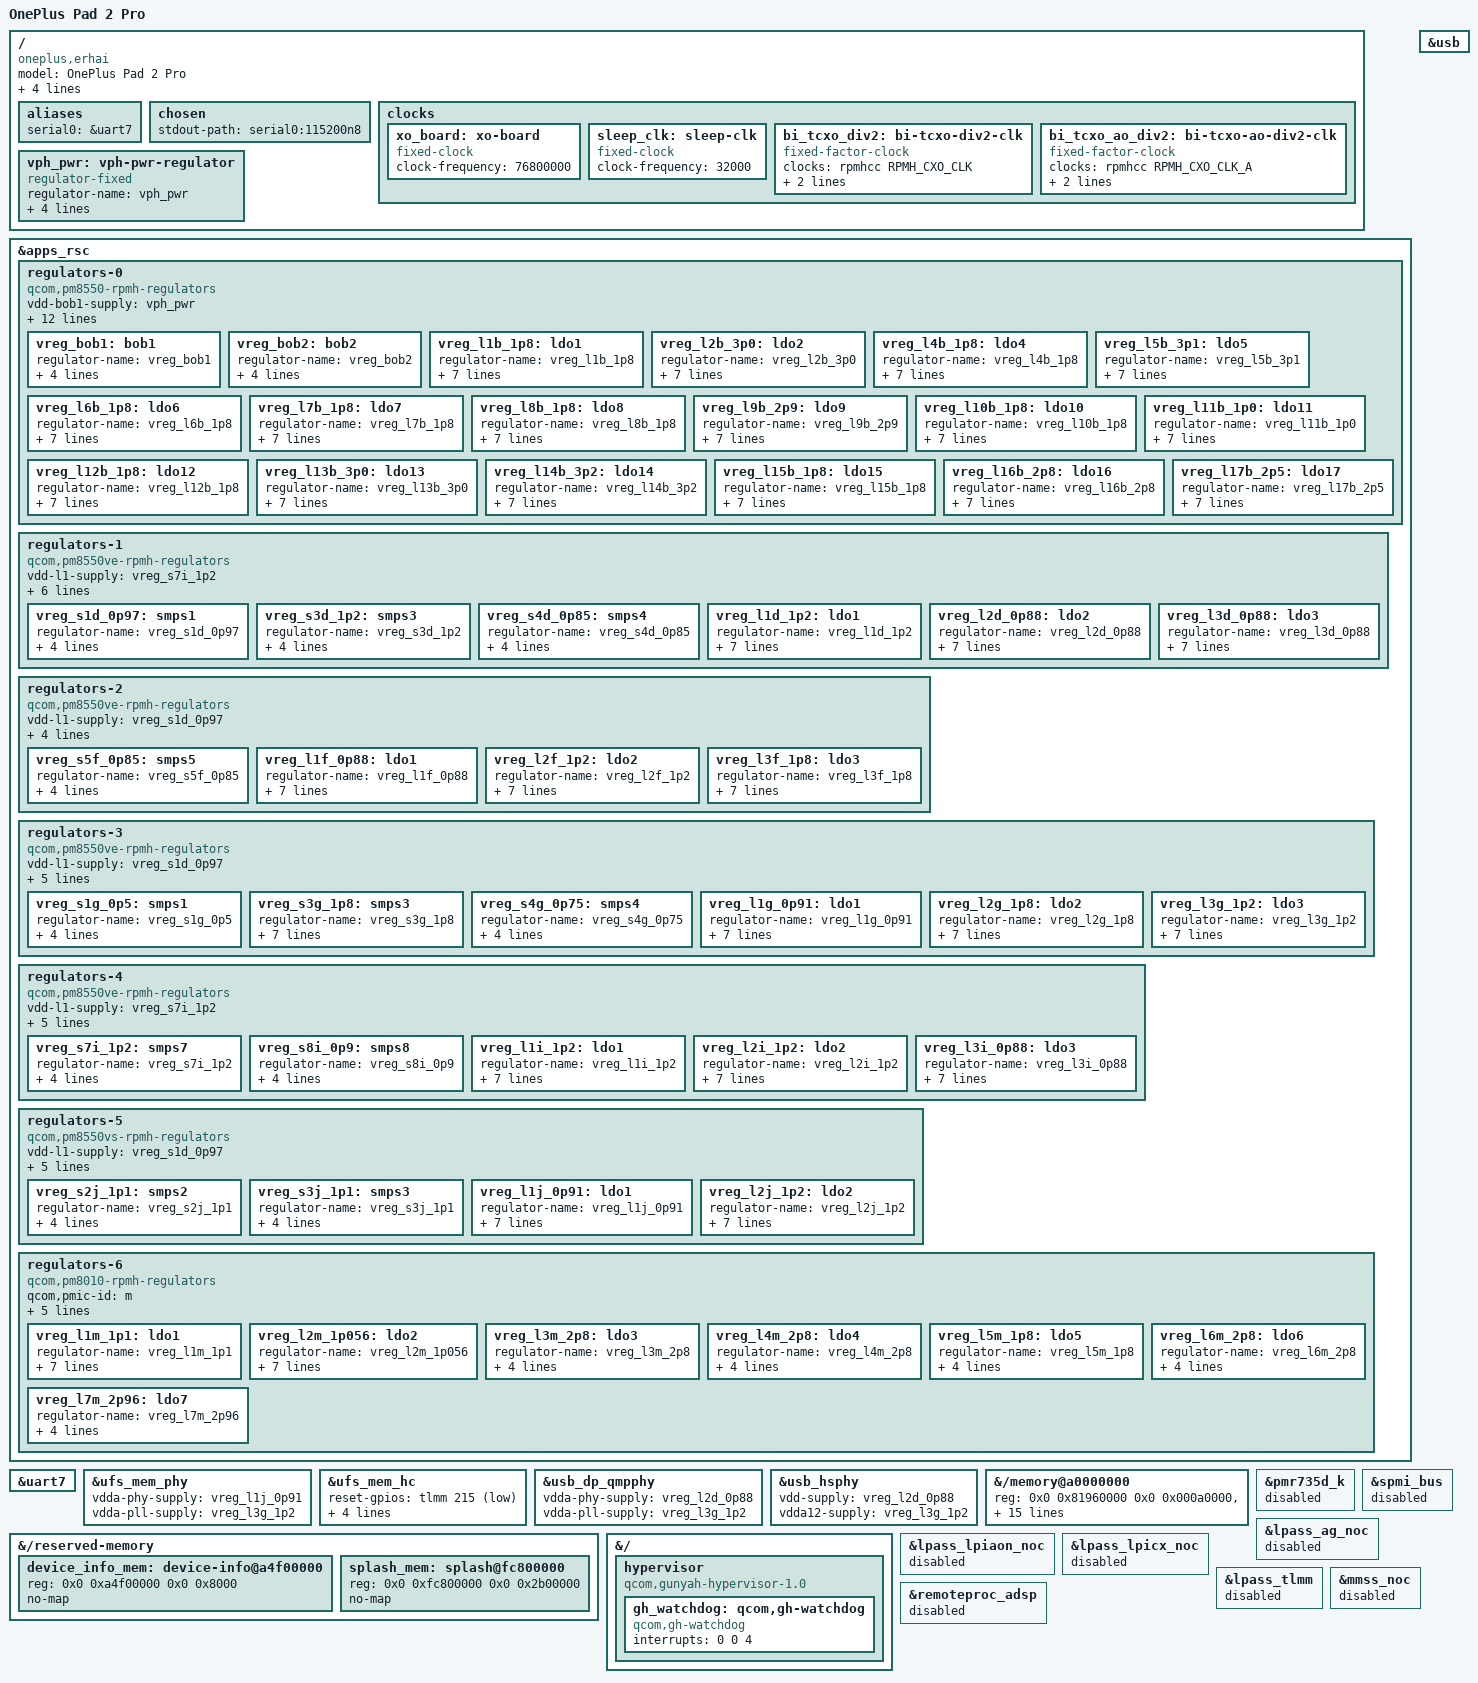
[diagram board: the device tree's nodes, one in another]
// SPDX-License-Identifier: BSD-3-Clause
/*
 * Copyright (c) 2026, OnePlus Pad 2 Pro (erhai) mainline contributors
 *
 * OnePlus Pad 2 Pro (codename "erhai") first-boot skeleton, structured
 * after the in-tree sm8750-xiaomi-piano.dts skeleton (same SM8750/sun
 * SoC). v0 scope: UART7 console, UFS storage, USB DWC3. Display/DSI,
 * touch, WLAN/BT, audio, sensors intentionally not enabled yet.
 *
 * Value provenance:
 *   (M) carried over from the in-tree SM8750 MTP / piano board files
 *   (R) cross-checked against the erhai live kernel DTB
 *       (vendor/erhai/board.dtb) and LineageOS
 *       android_kernel_oneplus_sm8750-devicetrees (erhai overlays)
 */

/dts-v1/;

#include <dt-bindings/gpio/gpio.h>
#include <dt-bindings/regulator/qcom,rpmh-regulator.h>
#include "sm8750.dtsi"
#include "pm8010.dtsi"
#include "pm8550.dtsi"
#define PMK8550VE_SID 8
#include "pm8550ve.dtsi"
#include "pmd8028.dtsi"
#include "pmih0108.dtsi"
#include "pmk8550.dtsi"
#include "pmr735d_a.dtsi"
#include "sm8750-pmics.dtsi"

/ {
	model = "OnePlus Pad 2 Pro";
	compatible = "oneplus,erhai", "qcom,sm8750";
	chassis-type = "tablet";

	/*
	 * (R) erhai live DTB / LineageOS sun-mtp-v8: SUN (0x26a) rev 1/2 and
	 * SUNP (0x27f) fallback entries. ABL-era matching is irrelevant on the
	 * SunUEFI handoff path; the kernel only needs sane IDs.
	 */
	qcom,msm-id = <0x100026a 0x20000>, <0x100027f 0x20000>;
	qcom,board-id = <0x40008 0>;

	aliases {
		serial0 = &uart7;
	};

	chosen {
		stdout-path = "serial0:115200n8";
	};

	clocks {
		xo_board: xo-board {
			compatible = "fixed-clock";
			clock-frequency = <76800000>;		/* (M) */
			#clock-cells = <0>;
		};

		sleep_clk: sleep-clk {
			compatible = "fixed-clock";
			clock-frequency = <32000>;		/* (M) */
			#clock-cells = <0>;
		};

		bi_tcxo_div2: bi-tcxo-div2-clk {
			compatible = "fixed-factor-clock";
			#clock-cells = <0>;

			clocks = <&rpmhcc RPMH_CXO_CLK>;
			clock-mult = <1>;
			clock-div = <2>;
		};

		bi_tcxo_ao_div2: bi-tcxo-ao-div2-clk {
			compatible = "fixed-factor-clock";
			#clock-cells = <0>;

			clocks = <&rpmhcc RPMH_CXO_CLK_A>;
			clock-mult = <1>;
			clock-div = <2>;
		};
	};

	vph_pwr: vph-pwr-regulator {
		compatible = "regulator-fixed";

		regulator-name = "vph_pwr";
		regulator-min-microvolt = <3700000>;		/* (M) */
		regulator-max-microvolt = <3700000>;		/* (M) */

		regulator-always-on;
		regulator-boot-on;
	};
};

&apps_rsc {
	/*
	 * Regulator network follows the SM8750 MTP power grid (v8 variant,
	 * same grid downstream sun-mtp-v8). Per-rail assignment for the
	 * piano board is carried from MTP and not yet device-verified. (M)
	 * Open question #10 tracks per-rail validation.
	 */
	regulators-0 {
		compatible = "qcom,pm8550-rpmh-regulators";

		vdd-bob1-supply = <&vph_pwr>;
		vdd-bob2-supply = <&vph_pwr>;
		vdd-l1-l4-l10-supply = <&vreg_s3g_1p8>;
		vdd-l2-l13-l14-supply = <&vreg_bob1>;
		vdd-l3-supply = <&vreg_s7i_1p2>;
		vdd-l5-l16-supply = <&vreg_bob1>;
		vdd-l6-l7-supply = <&vreg_bob1>;
		vdd-l8-l9-supply = <&vreg_bob1>;
		vdd-l11-supply = <&vreg_s7i_1p2>;
		vdd-l12-supply = <&vreg_s3g_1p8>;
		vdd-l15-supply = <&vreg_s3g_1p8>;
		vdd-l17-supply = <&vreg_bob2>;

		qcom,pmic-id = "b";

		vreg_bob1: bob1 {
			regulator-name = "vreg_bob1";
			regulator-min-microvolt = <3008000>;
			regulator-max-microvolt = <4000000>;
			regulator-initial-mode = <RPMH_REGULATOR_MODE_HPM>;
		};

		vreg_bob2: bob2 {
			regulator-name = "vreg_bob2";
			regulator-min-microvolt = <2704000>;
			regulator-max-microvolt = <3008000>;
			regulator-initial-mode = <RPMH_REGULATOR_MODE_HPM>;
		};

		vreg_l1b_1p8: ldo1 {
			regulator-name = "vreg_l1b_1p8";
			regulator-min-microvolt = <1800000>;
			regulator-max-microvolt = <1800000>;
			regulator-initial-mode = <RPMH_REGULATOR_MODE_HPM>;
			regulator-allow-set-load;
			regulator-allowed-modes = <RPMH_REGULATOR_MODE_LPM
						   RPMH_REGULATOR_MODE_HPM>;
		};

		vreg_l2b_3p0: ldo2 {
			regulator-name = "vreg_l2b_3p0";
			regulator-min-microvolt = <3008000>;
			regulator-max-microvolt = <3048000>;
			regulator-initial-mode = <RPMH_REGULATOR_MODE_HPM>;
			regulator-allow-set-load;
			regulator-allowed-modes = <RPMH_REGULATOR_MODE_LPM
						   RPMH_REGULATOR_MODE_HPM>;
		};

		vreg_l4b_1p8: ldo4 {
			regulator-name = "vreg_l4b_1p8";
			regulator-min-microvolt = <1800000>;
			regulator-max-microvolt = <1800000>;
			regulator-initial-mode = <RPMH_REGULATOR_MODE_HPM>;
			regulator-allow-set-load;
			regulator-allowed-modes = <RPMH_REGULATOR_MODE_LPM
						   RPMH_REGULATOR_MODE_HPM>;
		};

		vreg_l5b_3p1: ldo5 {
			regulator-name = "vreg_l5b_3p1";
			regulator-min-microvolt = <3100000>;
			regulator-max-microvolt = <3148000>;
			regulator-initial-mode = <RPMH_REGULATOR_MODE_HPM>;
			regulator-allow-set-load;
			regulator-allowed-modes = <RPMH_REGULATOR_MODE_LPM
						   RPMH_REGULATOR_MODE_HPM>;
		};

		vreg_l6b_1p8: ldo6 {
			regulator-name = "vreg_l6b_1p8";
			regulator-min-microvolt = <1800000>;
			regulator-max-microvolt = <3008000>;
			regulator-initial-mode = <RPMH_REGULATOR_MODE_HPM>;
			regulator-allow-set-load;
			regulator-allowed-modes = <RPMH_REGULATOR_MODE_LPM
						   RPMH_REGULATOR_MODE_HPM>;
		};

		vreg_l7b_1p8: ldo7 {
			regulator-name = "vreg_l7b_1p8";
			regulator-min-microvolt = <1800000>;
			regulator-max-microvolt = <3008000>;
			regulator-initial-mode = <RPMH_REGULATOR_MODE_HPM>;
			regulator-allow-set-load;
			regulator-allowed-modes = <RPMH_REGULATOR_MODE_LPM
						   RPMH_REGULATOR_MODE_HPM>;
		};

		vreg_l8b_1p8: ldo8 {
			regulator-name = "vreg_l8b_1p8";
			regulator-min-microvolt = <1800000>;
			regulator-max-microvolt = <3008000>;
			regulator-initial-mode = <RPMH_REGULATOR_MODE_HPM>;
			regulator-allow-set-load;
			regulator-allowed-modes = <RPMH_REGULATOR_MODE_LPM
						   RPMH_REGULATOR_MODE_HPM>;
		};

		vreg_l9b_2p9: ldo9 {
			regulator-name = "vreg_l9b_2p9";
			regulator-min-microvolt = <2960000>;
			regulator-max-microvolt = <3008000>;
			regulator-initial-mode = <RPMH_REGULATOR_MODE_HPM>;
			regulator-allow-set-load;
			regulator-allowed-modes = <RPMH_REGULATOR_MODE_LPM
						   RPMH_REGULATOR_MODE_HPM>;
		};

		vreg_l10b_1p8: ldo10 {
			regulator-name = "vreg_l10b_1p8";
			regulator-min-microvolt = <1800000>;
			regulator-max-microvolt = <1800000>;
			regulator-initial-mode = <RPMH_REGULATOR_MODE_HPM>;
			regulator-allow-set-load;
			regulator-allowed-modes = <RPMH_REGULATOR_MODE_LPM
						   RPMH_REGULATOR_MODE_HPM>;
		};

		vreg_l11b_1p0: ldo11 {
			regulator-name = "vreg_l11b_1p0";
			regulator-min-microvolt = <1064000>;
			regulator-max-microvolt = <1292000>;
			regulator-initial-mode = <RPMH_REGULATOR_MODE_HPM>;
			regulator-allow-set-load;
			regulator-allowed-modes = <RPMH_REGULATOR_MODE_LPM
						   RPMH_REGULATOR_MODE_HPM>;
		};

		vreg_l12b_1p8: ldo12 {
			regulator-name = "vreg_l12b_1p8";
			regulator-min-microvolt = <1200000>;
			regulator-max-microvolt = <1800000>;
			regulator-initial-mode = <RPMH_REGULATOR_MODE_HPM>;
			regulator-allow-set-load;
			regulator-allowed-modes = <RPMH_REGULATOR_MODE_LPM
						   RPMH_REGULATOR_MODE_HPM>;
		};

		vreg_l13b_3p0: ldo13 {
			regulator-name = "vreg_l13b_3p0";
			regulator-min-microvolt = <3000000>;
			regulator-max-microvolt = <3000000>;
			regulator-initial-mode = <RPMH_REGULATOR_MODE_HPM>;
			regulator-allow-set-load;
			regulator-allowed-modes = <RPMH_REGULATOR_MODE_LPM
						   RPMH_REGULATOR_MODE_HPM>;
		};

		vreg_l14b_3p2: ldo14 {
			regulator-name = "vreg_l14b_3p2";
			regulator-min-microvolt = <3200000>;
			regulator-max-microvolt = <3200000>;
			regulator-initial-mode = <RPMH_REGULATOR_MODE_HPM>;
			regulator-allow-set-load;
			regulator-allowed-modes = <RPMH_REGULATOR_MODE_LPM
						   RPMH_REGULATOR_MODE_HPM>;
		};

		vreg_l15b_1p8: ldo15 {
			regulator-name = "vreg_l15b_1p8";
			regulator-min-microvolt = <1800000>;
			regulator-max-microvolt = <1800000>;
			regulator-initial-mode = <RPMH_REGULATOR_MODE_HPM>;
			regulator-allow-set-load;
			regulator-allowed-modes = <RPMH_REGULATOR_MODE_LPM
						   RPMH_REGULATOR_MODE_HPM>;
		};

		vreg_l16b_2p8: ldo16 {
			regulator-name = "vreg_l16b_2p8";
			regulator-min-microvolt = <2800000>;
			regulator-max-microvolt = <2800000>;
			regulator-initial-mode = <RPMH_REGULATOR_MODE_HPM>;
			regulator-allow-set-load;
			regulator-allowed-modes = <RPMH_REGULATOR_MODE_LPM
						   RPMH_REGULATOR_MODE_HPM>;
		};

		vreg_l17b_2p5: ldo17 {
			regulator-name = "vreg_l17b_2p5";
			regulator-min-microvolt = <2504000>;
			regulator-max-microvolt = <2504000>;
			regulator-initial-mode = <RPMH_REGULATOR_MODE_HPM>;
			regulator-allow-set-load;
			regulator-allowed-modes = <RPMH_REGULATOR_MODE_LPM
						   RPMH_REGULATOR_MODE_HPM>;
		};
	};

	regulators-1 {
		compatible = "qcom,pm8550ve-rpmh-regulators";

		vdd-l1-supply = <&vreg_s7i_1p2>;
		vdd-l2-supply = <&vreg_s1d_0p97>;
		vdd-l3-supply = <&vreg_s1d_0p97>;
		vdd-s1-supply = <&vph_pwr>;
		vdd-s3-supply = <&vph_pwr>;
		vdd-s4-supply = <&vph_pwr>;

		qcom,pmic-id = "d";

		vreg_s1d_0p97: smps1 {
			regulator-name = "vreg_s1d_0p97";
			regulator-min-microvolt = <880000>;
			regulator-max-microvolt = <1100000>;
			regulator-initial-mode = <RPMH_REGULATOR_MODE_HPM>;
		};

		vreg_s3d_1p2: smps3 {
			regulator-name = "vreg_s3d_1p2";
			regulator-min-microvolt = <1200000>;
			regulator-max-microvolt = <1300000>;
			regulator-initial-mode = <RPMH_REGULATOR_MODE_HPM>;
		};

		vreg_s4d_0p85: smps4 {
			regulator-name = "vreg_s4d_0p85";
			regulator-min-microvolt = <852000>;
			regulator-max-microvolt = <1036000>;
			regulator-initial-mode = <RPMH_REGULATOR_MODE_HPM>;
		};

		vreg_l1d_1p2: ldo1 {
			regulator-name = "vreg_l1d_1p2";
			regulator-min-microvolt = <1200000>;
			regulator-max-microvolt = <1200000>;
			regulator-initial-mode = <RPMH_REGULATOR_MODE_HPM>;
			regulator-allow-set-load;
			regulator-allowed-modes = <RPMH_REGULATOR_MODE_LPM
						   RPMH_REGULATOR_MODE_HPM>;
		};

		vreg_l2d_0p88: ldo2 {
			regulator-name = "vreg_l2d_0p88";
			regulator-min-microvolt = <880000>;
			regulator-max-microvolt = <912000>;
			regulator-initial-mode = <RPMH_REGULATOR_MODE_HPM>;
			regulator-allow-set-load;
			regulator-allowed-modes = <RPMH_REGULATOR_MODE_LPM
						   RPMH_REGULATOR_MODE_HPM>;
		};

		vreg_l3d_0p88: ldo3 {
			regulator-name = "vreg_l3d_0p88";
			regulator-min-microvolt = <880000>;
			regulator-max-microvolt = <920000>;
			regulator-initial-mode = <RPMH_REGULATOR_MODE_HPM>;
			regulator-allow-set-load;
			regulator-allowed-modes = <RPMH_REGULATOR_MODE_LPM
						   RPMH_REGULATOR_MODE_HPM>;
		};
	};

	regulators-2 {
		compatible = "qcom,pm8550ve-rpmh-regulators";

		vdd-l1-supply = <&vreg_s1d_0p97>;
		vdd-l2-supply = <&vreg_s7i_1p2>;
		vdd-l3-supply = <&vreg_s3g_1p8>;
		vdd-s5-supply = <&vph_pwr>;

		qcom,pmic-id = "f";

		vreg_s5f_0p85: smps5 {
			regulator-name = "vreg_s5f_0p85";
			regulator-min-microvolt = <852000>;
			regulator-max-microvolt = <1000000>;
			regulator-initial-mode = <RPMH_REGULATOR_MODE_HPM>;
		};

		vreg_l1f_0p88: ldo1 {
			regulator-name = "vreg_l1f_0p88";
			regulator-min-microvolt = <880000>;
			regulator-max-microvolt = <920000>;
			regulator-initial-mode = <RPMH_REGULATOR_MODE_HPM>;
			regulator-allow-set-load;
			regulator-allowed-modes = <RPMH_REGULATOR_MODE_LPM
						   RPMH_REGULATOR_MODE_HPM>;
		};

		vreg_l2f_1p2: ldo2 {
			regulator-name = "vreg_l2f_1p2";
			regulator-min-microvolt = <1200000>;
			regulator-max-microvolt = <1200000>;
			regulator-initial-mode = <RPMH_REGULATOR_MODE_HPM>;
			regulator-allow-set-load;
			regulator-allowed-modes = <RPMH_REGULATOR_MODE_LPM
						   RPMH_REGULATOR_MODE_HPM>;
		};

		vreg_l3f_1p8: ldo3 {
			regulator-name = "vreg_l3f_1p8";
			regulator-min-microvolt = <1800000>;
			regulator-max-microvolt = <1800000>;
			regulator-initial-mode = <RPMH_REGULATOR_MODE_HPM>;
			regulator-allow-set-load;
			regulator-allowed-modes = <RPMH_REGULATOR_MODE_LPM
						   RPMH_REGULATOR_MODE_HPM>;
		};
	};

	regulators-3 {
		compatible = "qcom,pm8550ve-rpmh-regulators";

		vdd-l1-supply = <&vreg_s1d_0p97>;
		vdd-l2-supply = <&vreg_s3g_1p8>;
		vdd-l3-supply = <&vreg_s7i_1p2>;
		vdd-s1-supply = <&vph_pwr>;
		vdd-s3-supply = <&vph_pwr>;

		qcom,pmic-id = "g";

		vreg_s1g_0p5: smps1 {
			regulator-name = "vreg_s1g_0p5";
			regulator-min-microvolt = <300000>;
			regulator-max-microvolt = <700000>;
			regulator-initial-mode = <RPMH_REGULATOR_MODE_HPM>;
		};

		vreg_s3g_1p8: smps3 {
			regulator-name = "vreg_s3g_1p8";
			regulator-min-microvolt = <1856000>;
			regulator-max-microvolt = <2000000>;
			regulator-initial-mode = <RPMH_REGULATOR_MODE_LPM>;
			regulator-allow-set-load;
			regulator-allowed-modes = <RPMH_REGULATOR_MODE_LPM
						   RPMH_REGULATOR_MODE_HPM>;
		};

		vreg_s4g_0p75: smps4 {
			regulator-name = "vreg_s4g_0p75";
			regulator-min-microvolt = <300000>;
			regulator-max-microvolt = <900000>;
			regulator-initial-mode = <RPMH_REGULATOR_MODE_HPM>;
		};

		vreg_l1g_0p91: ldo1 {
			regulator-name = "vreg_l1g_0p91";
			regulator-min-microvolt = <912000>;
			regulator-max-microvolt = <936000>;
			regulator-initial-mode = <RPMH_REGULATOR_MODE_HPM>;
			regulator-allow-set-load;
			regulator-allowed-modes = <RPMH_REGULATOR_MODE_LPM
						   RPMH_REGULATOR_MODE_HPM>;
		};

		vreg_l2g_1p8: ldo2 {
			regulator-name = "vreg_l2g_1p8";
			regulator-min-microvolt = <1200000>;
			regulator-max-microvolt = <1860000>;
			regulator-initial-mode = <RPMH_REGULATOR_MODE_HPM>;
			regulator-allow-set-load;
			regulator-allowed-modes = <RPMH_REGULATOR_MODE_LPM
						   RPMH_REGULATOR_MODE_HPM>;
		};

		vreg_l3g_1p2: ldo3 {
			regulator-name = "vreg_l3g_1p2";
			regulator-min-microvolt = <1200000>;
			regulator-max-microvolt = <1256000>;
			regulator-initial-mode = <RPMH_REGULATOR_MODE_HPM>;
			regulator-allow-set-load;
			regulator-allowed-modes = <RPMH_REGULATOR_MODE_LPM
						   RPMH_REGULATOR_MODE_HPM>;
		};
	};

	regulators-4 {
		compatible = "qcom,pm8550ve-rpmh-regulators";

		vdd-l1-supply = <&vreg_s7i_1p2>;
		vdd-l2-supply = <&vreg_s7i_1p2>;
		vdd-l3-supply = <&vreg_s1d_0p97>;
		vdd-s7-supply = <&vph_pwr>;
		vdd-s8-supply = <&vph_pwr>;

		qcom,pmic-id = "i";

		vreg_s7i_1p2: smps7 {
			regulator-name = "vreg_s7i_1p2";
			regulator-min-microvolt = <1224000>;
			regulator-max-microvolt = <1340000>;
			regulator-initial-mode = <RPMH_REGULATOR_MODE_HPM>;
		};

		vreg_s8i_0p9: smps8 {
			regulator-name = "vreg_s8i_0p9";
			regulator-min-microvolt = <900000>;
			regulator-max-microvolt = <972000>;
			regulator-initial-mode = <RPMH_REGULATOR_MODE_HPM>;
		};

		vreg_l1i_1p2: ldo1 {
			regulator-name = "vreg_l1i_1p2";
			regulator-min-microvolt = <1200000>;
			regulator-max-microvolt = <1200000>;
			regulator-initial-mode = <RPMH_REGULATOR_MODE_HPM>;
			regulator-allow-set-load;
			regulator-allowed-modes = <RPMH_REGULATOR_MODE_LPM
						   RPMH_REGULATOR_MODE_HPM>;
		};

		vreg_l2i_1p2: ldo2 {
			regulator-name = "vreg_l2i_1p2";
			regulator-min-microvolt = <1200000>;
			regulator-max-microvolt = <1200000>;
			regulator-initial-mode = <RPMH_REGULATOR_MODE_HPM>;
			regulator-allow-set-load;
			regulator-allowed-modes = <RPMH_REGULATOR_MODE_LPM
						   RPMH_REGULATOR_MODE_HPM>;
		};

		vreg_l3i_0p88: ldo3 {
			regulator-name = "vreg_l3i_0p88";
			regulator-min-microvolt = <880000>;
			regulator-max-microvolt = <912000>;
			regulator-initial-mode = <RPMH_REGULATOR_MODE_HPM>;
			regulator-allow-set-load;
			regulator-allowed-modes = <RPMH_REGULATOR_MODE_LPM
						   RPMH_REGULATOR_MODE_HPM>;
		};
	};

	regulators-5 {
		compatible = "qcom,pm8550vs-rpmh-regulators";

		vdd-l1-supply = <&vreg_s1d_0p97>;
		vdd-l2-supply = <&vreg_s7i_1p2>;
		vdd-s2-supply = <&vph_pwr>;
		vdd-s3-supply = <&vph_pwr>;
		vdd-s4-supply = <&vph_pwr>;

		qcom,pmic-id = "j";

		vreg_s2j_1p1: smps2 {
			regulator-name = "vreg_s2j_1p1";
			regulator-min-microvolt = <1000000>;
			regulator-max-microvolt = <1100000>;
			regulator-initial-mode = <RPMH_REGULATOR_MODE_HPM>;
		};

		vreg_s3j_1p1: smps3 {
			regulator-name = "vreg_s3j_1p1";
			regulator-min-microvolt = <1000000>;
			regulator-max-microvolt = <1100000>;
			regulator-initial-mode = <RPMH_REGULATOR_MODE_HPM>;
		};

		vreg_l1j_0p91: ldo1 {
			regulator-name = "vreg_l1j_0p91";
			regulator-min-microvolt = <880000>;
			regulator-max-microvolt = <920000>;
			regulator-initial-mode = <RPMH_REGULATOR_MODE_HPM>;
			regulator-allow-set-load;
			regulator-allowed-modes = <RPMH_REGULATOR_MODE_LPM
						   RPMH_REGULATOR_MODE_HPM>;
		};

		vreg_l2j_1p2: ldo2 {
			regulator-name = "vreg_l2j_1p2";
			regulator-min-microvolt = <1200000>;
			regulator-max-microvolt = <1200000>;
			regulator-initial-mode = <RPMH_REGULATOR_MODE_HPM>;
			regulator-allow-set-load;
			regulator-allowed-modes = <RPMH_REGULATOR_MODE_LPM
						   RPMH_REGULATOR_MODE_HPM>;
		};
	};

	regulators-6 {
		compatible = "qcom,pm8010-rpmh-regulators";
		qcom,pmic-id = "m";

		vdd-l1-l2-supply = <&vreg_s7i_1p2>;
		vdd-l3-l4-supply = <&vreg_bob2>;
		vdd-l5-supply = <&vreg_s3g_1p8>;
		vdd-l6-supply = <&vreg_bob1>;
		vdd-l7-supply = <&vreg_bob1>;

		vreg_l1m_1p1: ldo1 {
			regulator-name = "vreg_l1m_1p1";
			regulator-min-microvolt = <1104000>;
			regulator-max-microvolt = <1104000>;
			regulator-initial-mode = <RPMH_REGULATOR_MODE_HPM>;
			regulator-allow-set-load;
			regulator-allowed-modes = <RPMH_REGULATOR_MODE_LPM
						   RPMH_REGULATOR_MODE_HPM>;
		};

		vreg_l2m_1p056: ldo2 {
			regulator-name = "vreg_l2m_1p056";
			regulator-min-microvolt = <1056000>;
			regulator-max-microvolt = <1056000>;
			regulator-initial-mode = <RPMH_REGULATOR_MODE_HPM>;
			regulator-allow-set-load;
			regulator-allowed-modes = <RPMH_REGULATOR_MODE_LPM
						   RPMH_REGULATOR_MODE_HPM>;
		};

		vreg_l3m_2p8: ldo3 {
			regulator-name = "vreg_l3m_2p8";
			regulator-min-microvolt = <2800000>;
			regulator-max-microvolt = <2800000>;
			regulator-initial-mode = <RPMH_REGULATOR_MODE_HPM>;
		};

		vreg_l4m_2p8: ldo4 {
			regulator-name = "vreg_l4m_2p8";
			regulator-min-microvolt = <2800000>;
			regulator-max-microvolt = <2800000>;
			regulator-initial-mode = <RPMH_REGULATOR_MODE_HPM>;
		};

		vreg_l5m_1p8: ldo5 {
			regulator-name = "vreg_l5m_1p8";
			regulator-min-microvolt = <1800000>;
			regulator-max-microvolt = <1800000>;
			regulator-initial-mode = <RPMH_REGULATOR_MODE_HPM>;
		};

		vreg_l6m_2p8: ldo6 {
			regulator-name = "vreg_l6m_2p8";
			regulator-min-microvolt = <2800000>;
			regulator-max-microvolt = <2800000>;
			regulator-initial-mode = <RPMH_REGULATOR_MODE_HPM>;
		};

		vreg_l7m_2p96: ldo7 {
			regulator-name = "vreg_l7m_2p96";
			regulator-min-microvolt = <2960000>;
			regulator-max-microvolt = <2960000>;
			regulator-initial-mode = <RPMH_REGULATOR_MODE_HPM>;
		};
	};

	/* No regulators-7 (pmic-id "n"): piano omits the second PM8010 die. (R) */
};
&uart7 {
	status = "okay";
};

/*
 * (M) SoC-generic UFS rails from the MTP/piano board file. The erhai live
 * DTB names vcc/vccq via phandles into the same PMIC rail set; refine the
 * exact rails after first boot.
 */
&ufs_mem_phy {
	vdda-phy-supply = <&vreg_l1j_0p91>;		/* (M) */
	vdda-pll-supply = <&vreg_l3g_1p2>;		/* (M) */

	status = "okay";
};

&ufs_mem_hc {
	reset-gpios = <&tlmm 215 GPIO_ACTIVE_LOW>;	/* (M) */

	vcc-supply = <&vreg_l17b_2p5>;			/* (M) */
	vcc-max-microamp = <1300000>;
	vccq-supply = <&vreg_l1d_1p2>;			/* (M) */
	vccq-max-microamp = <1200000>;

	status = "okay";
};

&usb {
	status = "okay";
};

&usb_dp_qmpphy {
	vdda-phy-supply = <&vreg_l2d_0p88>;		/* (M) */
	vdda-pll-supply = <&vreg_l3g_1p2>;		/* (M) */

	status = "okay";
};

&usb_hsphy {
	vdd-supply = <&vreg_l2d_0p88>;			/* (M) */
	vdda12-supply = <&vreg_l3g_1p2>;		/* (M) */

	status = "okay";
};

/*
 * Real erhai DRAM map, copied verbatim from the live vendor FDT
 * (vendor/erhai/board.dtb, /memory reg). ABL fills this for the Android boot;
 * a raw UEFI handoff must ship it in the DTB instead of growing the property
 * at runtime: growing it shifts libfdt node offsets, and the following
 * /chosen writes then land on stale nodes (FDT_ERR_BADOFFSET / wrong
 * bootargs). The stage-0 boot manager no longer patches /memory.
 */
&{/memory@a0000000} {
	reg = <0x0 0x81960000 0x0 0x000a0000>,
	      <0x0 0x81a40000 0x0 0x001c0000>,
	      <0x0 0x81cf4000 0x0 0x0000c000>,
	      <0x0 0x82460000 0x0 0x00040000>,
	      <0x0 0xbe360000 0x0 0x16ac3000>,
	      <0x0 0xd5100000 0x0 0x02f00000>,
	      <0x0 0xd8600000 0x0 0x00000000>,
	      /* Split around the display splash/FB (0xfc800000-0xff2fffff). It is
	       * not System RAM: including it here makes memremap() WARN and breaks
	       * simpledrm/efi_earlycon framebuffer remapping. */
	      <0x0 0xe3720000 0x0 0x090e0000>,
	      <0x0 0xff300000 0x0 0x00500000>,
	      <0x8 0x80000000 0x0 0x2f6fd000>,
	      <0x8 0xb0000000 0x0 0x05500000>,
	      <0xa 0x00000000 0x2 0x00000000>,
	      <0x8 0xc0000000 0x1 0x40000000>,
	      <0x0 0x82800000 0x0 0x18800000>,
	      <0x0 0xa3e80000 0x0 0x14180000>,
	      <0x0 0xb81c0000 0x0 0x05770000>;
};

/* Vendor device-info page inside usable RAM; keep it out of the page allocator. */
&{/reserved-memory} {
	device_info_mem: device-info@a4f00000 {
		reg = <0x0 0xa4f00000 0x0 0x8000>;
		no-map;
	};

	splash_mem: splash@fc800000 {
		reg = <0x0 0xfc800000 0x0 0x2b00000>;
		no-map;
	};
};

/*
 * Gunyah/QHEE hypervisor virtual watchdog. The Android kernel probes
 * "qcom,gh-watchdog" and the driver disables it; without this node the
 * mainline kernel leaves the OnePlus ABL-armed Apps Watchdog running and the
 * SoC resets into QUSB_BULK/EDL a few seconds after the handoff.
 */
&{/} {
	hypervisor {
		compatible = "qcom,gunyah-hypervisor-1.0", "qcom,gunyah-hypervisor", "simple-bus";
		#address-cells = <2>;
		#size-cells = <0>;

		gh_watchdog: qcom,gh-watchdog {
			compatible = "qcom,gh-watchdog";
			interrupts = <0 0 4>;
		};
	};
};

/*
 * The PMR735D borrowed from the piano PMIC set is not populated on erhai:
 * the qcom-spmi-pmic MFD probe at SPMI USID 0x0a fails with -EIO, and the
 * failed parent leaves its children without a regmap. Keep it disabled until
 * the erhai PMIC layout is confirmed from the vendor DTB.
 */
&pmr735d_k {
	status = "disabled";
};

/*
 * The inherited piano PMIC set does not match erhai and every probe that
 * reaches the SPMI arbiter fails its channel-status check (-EIO, WARN in
 * pmic_arb_check_chnl_status_v1). Keep the whole bus off for the RAM-shell
 * bring-up; the UEFI leaves display/rails powered, and the initramfs shell
 * does not need PMIC regulators.
 */
&spmi_bus {
	status = "disabled";
};

/*
 * LPASS/ADSP and its NoC interconnects are not needed for the RAM shell and
 * currently hang the kernel after lpass_lpicx_noc probe (device falls into
 * QUSB_BULK). Keep the whole audio subsystem off until it is brought up
 * deliberately.
 */
&lpass_ag_noc {
	status = "disabled";
};
&lpass_lpiaon_noc {
	status = "disabled";
};
&lpass_lpicx_noc {
	status = "disabled";
};
&lpass_tlmm {
	status = "disabled";
};
&remoteproc_adsp {
	status = "disabled";
};

/*
 * mmss_noc depends on apps_bcm_voter -> RPMh, which is unavailable while the
 * SPMI bus is disabled. The multimedia NoC is not needed for the RAM shell.
 */
&mmss_noc {
	status = "disabled";
};
